# R7FA8M1AH register map
Vendor: Renesas; Series: RA8; File version: 1.2
CPU: CM85 r0p0, little endian, MPU, FPU, VTOR, 4 interrupt priority bits
Registers are 32-bit, read-write, reset 0x0 unless marked. A register's access mark holds for its fields unless they carry their own. Offsets are from the block's base; [hi:lo] are bit positions.

## EDMAC0 — DMA Controller for the Ethernet Controller Channel 0
Base 0x40354000
Same registers: EDMAC0_NS 0x50354000
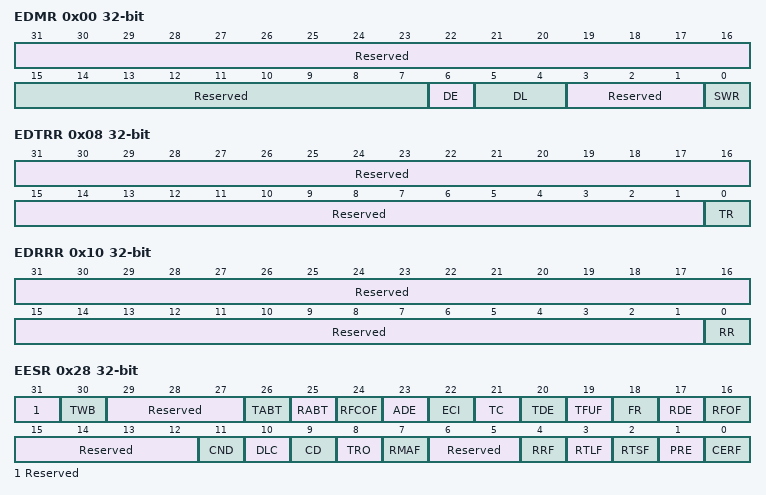
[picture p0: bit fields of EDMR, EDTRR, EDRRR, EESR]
0x00 EDMR — EDMAC Mode Register
  [31:16] Reserved — These bits are read as 0000000000000000. The write value should be 0000000000000000.
  [15:7] Reserved — These bits are read as 000000000. The write value should be 000000000.
  [6] DE — Big Endian Mode/Little Endian ModeNOTE: This setting applies to data for the transmit/receive buffer. It does not apply to transmit/receive descriptors and registers.
    0=Big endian mode; 1=Little endian mode
  [5:4] DL — Transmit/Receive DescriptorLength
    0=16 bytes; 1=32 bytes; 2=64 bytes; 3=16 bytes
  [3:1] Reserved — These bits are read as 000. The write value should be 000.
  [0] SWR wo — Software Reset
    0=no effect; 1=the corresponding channels of the EDMAC and ETHERC are reset. Registers TDLAR, RDLAR, RMFCR, TFUCR, and RFOCR are not reset.
0x08 EDTRR — EDMAC Transmit Request Register
  [31:1] Reserved — These bits are read as 0000000000000000000000000000000. The write value should be 0000000000000000000000000000000.
  [0] TR wo — Transmit Request
    0=no effect; 1=When 1 is written, the EDMAC reads the corresponding descriptor and transmits frames where the TD0.TACT bit is 1. The TR bit becomes 0 after all the valid frames are transmitted.
0x10 EDRRR — EDMAC Receive Request Register
  [31:1] Reserved — These bits are read as 0000000000000000000000000000000. The write value should be 0000000000000000000000000000000.
  [0] RR — Receive Request
    0=Receive function is disabled; 1=Receive descriptor is read, and the receive function is enabled
0x18 TDLAR — Transmit Descriptor List Start Address Register
  [31:0] TDLAR — The start address of the transmit descriptor list is set. Set the start address according to the descriptor length selected by the EDMR.DL[1:0] bits.16-byte boundary: Lower 4 bits = 0000b32-byte boundary: Lower 5 bits = 00000b64-byte boundary: Lower 6 bits = 000000b
0x20 RDLAR — Receive Descriptor List Start Address Register
  [31:0] RDLAR — The start address of the receive descriptor list is set. Set the start address according to the descriptor length selected by the EDMR.DL[1:0] bits.16-byte boundary: Lower 4 bits = 0000b32-byte boundary: Lower 5 bits = 00000b64-byte boundary: Lower 6 bits = 000000b
0x28 EESR — ETHERC/EDMAC Status Register
  [31] Reserved — This bit is read as 0. The write value should be 0.
  [30] TWB write-1-clears read-modifies — Write-Back Complete Flag
    0=Write-back has not been completed, or no transmission has been requested; 1=Write-back to the transmit descriptor has been completed
  [29:27] Reserved — These bits are read as 000. The write value should be 000.
  [26] TABT write-1-clears read-modifies — Transmit Abort Detect Flag
    0=Frame transmission has not been aborted or no transmission has been requested; 1=Frame transmission has been aborted
  [25] RABT write-1-clears read-modifies — Receive Abort Detect Flag
    0=Frame reception has not been aborted or no reception has been requested; 1=Frame reception has been aborted
  [24] RFCOF write-1-clears read-modifies — Receive Frame Counter Overflow Flag
    0=Receive frame counter has not overflowed; 1=Receive frame counter has overflowed
  [23] ADE write-1-clears read-modifies — Address Error Flag
    0=Invalid memory address has not been detected (normal operation); 1=Invalid memory address has been detected
  [22] ECI ro — ETHERC Status Register Source FlagNOTE: When the source in the ETHERCn.ECSR register is cleared, the ECI flag is also cleared.
    0=ETHERC status interrupt source has not been detected; 1=ETHERC status interrupt source has been detected
  [21] TC write-1-clears read-modifies — Frame Transfer Complete Flag
    0=Transfer have not been completed, or no transfer has been requested; 1=All frames indicated by the transmit descriptor have been completely transferred to the transmit FIFO
  [20] TDE write-1-clears read-modifies — Transmit Descriptor Empty Flag
    0=The EDMAC detects that the transmit descriptor valid bit (TDn.TACT) is 1; 1=The EDMAC detects that the transmit descriptor valid bit (TDn.TACT) is 0
  [19] TFUF write-1-clears read-modifies — Transmit FIFO Underflow Flag
    0=Underflow has not occurred; 1=Underflow has occurred
  [18] FR write-1-clears read-modifies — Frame Receive Flag
    0=Frame has not been received; 1=Frame has been received. Update of the receive descriptor is complete.
  [17] RDE write-1-clears read-modifies — Receive Descriptor Empty Flag
    0=The EDMAC detects that the receive descriptor valid bit (RDn.RACT) is 1; 1=The EDMAC detects that the receive descriptor valid bit (RDn.RACT) is 0
  [16] RFOF write-1-clears read-modifies — Receive FIFO Overflow Flag
    0=Overflow has not occurred; 1=Overflow has occurred
  [15:12] Reserved — These bits are read as 0000. The write value should be 0000.
  [11] CND write-1-clears read-modifies — Carrier Not Detect Flag
    0=A carrier has been detected when transmission starts; 1=A carrier has not been detected during preamble transmission
  [10] DLC write-1-clears read-modifies — Loss of Carrier Detect Flag
    0=Loss of carrier has not been detected; 1=Loss of carrier has been detected during frame transmission
  [9] CD write-1-clears read-modifies — Late Collision Detect Flag
    0=Late collision has not been detected; 1=Late collision has been detected during frame transmission
  [8] TRO write-1-clears read-modifies — Transmit Retry Over Flag
    0=Transmit retry-over condition has not been detected; 1=Transmit retry-over condition has been detected
  [7] RMAF write-1-clears read-modifies — Multicast Address Frame Receive Flag
    0=Multicast address frame has not been received; 1=Multicast address frame has been received
  [6:5] Reserved — These bits are read as 00. The write value should be 00.
  [4] RRF write-1-clears read-modifies — Alignment Error Flag
    0=Alignment error has not been detected; 1=Alignment error has been detected
  [3] RTLF write-1-clears read-modifies — Frame-Too-Long Error Flag
    0=Frame-too-long error has not been detected; 1=Frame-too-long error has been detected
  [2] RTSF write-1-clears read-modifies — Frame-Too-Short Error Flag
    0=Frame-too-short error has not been detected; 1=Frame-too-short error has been detected
  [1] PRE write-1-clears read-modifies — PHY-LSI Receive Error Flag
    0=PHY-LSI receive error has not been detected; 1=PHY-LSI receive error has been detected
  [0] CERF write-1-clears read-modifies — CRC Error Flag
    0=CRC error has not been detected; 1=CRC error has been detected
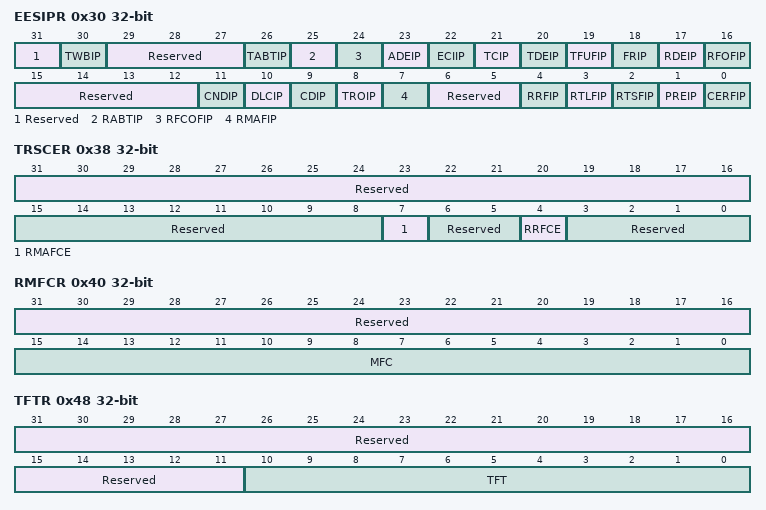
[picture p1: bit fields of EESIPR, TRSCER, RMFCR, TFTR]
0x30 EESIPR — ETHERC/EDMAC Status Interrupt Enable Register
  [31] Reserved — This bit is read as 0. The write value should be 0.
  [30] TWBIP — Write-Back Complete Interrupt Request Enable
    0=Write-back complete interrupt request is disabled; 1=Write-back complete interrupt request is enabled
  [29:27] Reserved — These bits are read as 000. The write value should be 000.
  [26] TABTIP — Transmit Abort Detect Interrupt Request Enable
    0=Transmit abort detect interrupt request is disabled; 1=Transmit abort detect interrupt request is enabled
  [25] RABTIP — Receive Abort Detect Interrupt Request Enable
    0=Receive abort detect interrupt request is disabled; 1=Receive abort detect interrupt request is enabled
  [24] RFCOFIP — Receive Frame Counter Overflow Interrupt Request Enable
    0=Receive frame counter overflow interrupt request is disabled; 1=Receive frame counter overflow interrupt request is enabled
  [23] ADEIP — Address Error Interrupt Request Enable
    0=Address error interrupt request is disabled; 1=Address error interrupt request is enabled
  [22] ECIIP — ETHERC Status Register Source Interrupt Request Enable
    0=ETHERC status interrupt request is disabled; 1=ETHERC status interrupt request is enabled
  [21] TCIP — Frame Transfer Complete Interrupt Request Enable
    0=Frame transmission complete interrupt request is disabled; 1=Frame transmission complete interrupt request is enabled
  [20] TDEIP — Transmit Descriptor Empty Interrupt Request Enable
    0=Transmit descriptor empty interrupt request is disabled; 1=Transmit descriptor empty interrupt request is enabled
  [19] TFUFIP — Transmit FIFO Underflow Interrupt Request Enable
    0=Underflow interrupt request is disabled; 1=Underflow interrupt request is enabled
  [18] FRIP — Frame Receive Interrupt Request Enable
    0=Frame reception interrupt request is disabled; 1=Frame reception interrupt request is enabled
  [17] RDEIP — Receive Descriptor Empty Interrupt Request Enable
    0=Receive descriptor empty interrupt request is disabled; 1=Receive descriptor empty interrupt request is enabled
  [16] RFOFIP — Receive FIFO Overflow Interrupt Request Enable
    0=Overflow interrupt request is disabled; 1=Overflow interrupt request is enabled
  [15:12] Reserved — These bits are read as 0000. The write value should be 0000.
  [11] CNDIP — Carrier Not Detect Interrupt Request Enable
    0=Carrier not detect interrupt request is disabled; 1=Carrier not detect interrupt request is enabled
  [10] DLCIP — Loss of Carrier Detect Interrupt Request Enable
    0=Loss of carrier detect interrupt request is disabled; 1=Loss of carrier detect interrupt request is enabled
  [9] CDIP — Late Collision Detect Interrupt Request Enable
    0=Late collision detect interrupt request is disabled; 1=Late collision detect interrupt request is enabled
  [8] TROIP — Transmit Retry Over Interrupt Request Enable
    0=Transmit retry over interrupt request is disabled; 1=Transmit retry over interrupt request is enabled
  [7] RMAFIP — Multicast Address Frame Receive Interrupt Request Enable
    0=Multicast address frame receive interrupt request is disabled; 1=Multicast address frame receive interrupt request is enabled
  [6:5] Reserved — These bits are read as 00. The write value should be 00.
  [4] RRFIP — Alignment Error Interrupt Request Enable
    0=Alignment error interrupt request is disabled; 1=Alignment error interrupt request is enabled
  [3] RTLFIP — Frame-Too-Long Error Interrupt Request Enable
    0=Frame-too-long error interrupt request is disabled; 1=Frame-too-long error interrupt request is enabled
  [2] RTSFIP — Frame-Too-Short Error Interrupt Request Enable
    0=Frame-too-short error interrupt request is disabled; 1=Frame-too-short error interrupt request is enabled
  [1] PREIP — PHY-LSI Receive Error Interrupt Request Enable
    0=PHY-LSI receive error interrupt request is disabled; 1=PHY-LSI receive error interrupt request is enabled
  [0] CERFIP — CRC Error Interrupt Request Enable
    0=CRC error interrupt request is disabled; 1=CRC error interrupt request is enabled
0x38 TRSCER — ETHERC/EDMAC Transmit/Receive Status Copy Enable Register
  [31:16] Reserved — These bits are read as 0000000000000000. The write value should be 0000000000000000.
  [15:8] Reserved — These bits are read as 00000000. The write value should be 00000000.
  [7] RMAFCE — RMAF Flag Copy Enable
    0=The EDMACn.EESR.RMAF flag status is reflected in the RDn.RFE bit of the receive descriptor; 1=The EDMACn.EESR.RMAF flag status is not reflected in the RDn.RFE bit of the receive descriptor
  [6:5] Reserved — These bits are read as 00. The write value should be 00.
  [4] RRFCE — RRF Flag Copy Enable
    0=The EDMACn.EESR.RRF flag status is reflected in the RDn.RFE bit of the receive descriptor; 1=The EDMACn.EESR.RRF flag status is not reflected in the RDn.RFE bit of the receive descriptor
  [3:0] Reserved — These bits are read as 0000. The write value should be 0000.
0x40 RMFCR — Missed-Frame Counter Register
  [31:16] Reserved — These bits are read as 0000000000000000. The write value should be 0000000000000000.
  [15:0] MFC write-clears — Missed-Frame CounterThese bits indicate the number of frames that are discarded and not transferred to the receive buffer during reception.
0x48 TFTR — Transmit FIFO Threshold Register
  [31:11] Reserved — These bits are read as 000000000000000000000. The write value should be 000000000000000000000.
  [10:0] TFT range 0x000..0x200 — Transmit FIFO Threshold00Dh to 200h: The threshold is the set value multiplied by 4. Example: 00Dh: 52 bytes 040h: 256 bytes 100h: 1024 bytes 200h: 2048 bytes
    0=Store and forward mode; other=others (The threshold is the set value multiplied by 4. (001h to 00Ch and 201h to 7FFh: Setting prohibited))
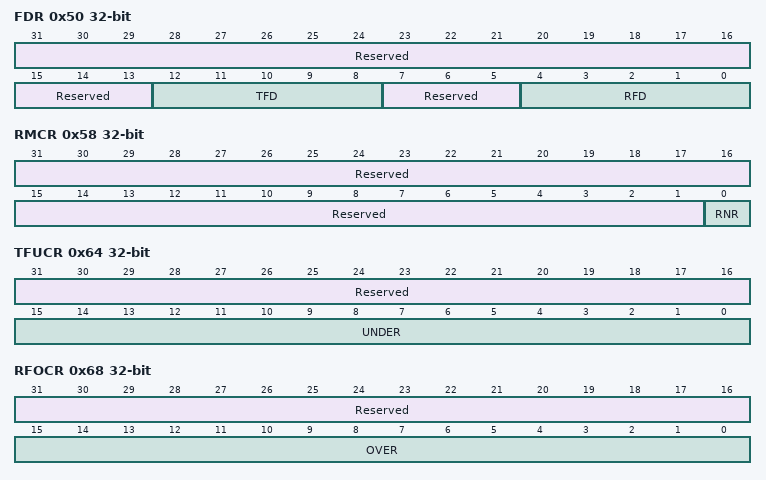
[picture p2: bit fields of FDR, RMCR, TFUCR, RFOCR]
0x50 FDR — Transmit FIFO Threshold Register
  [31:13] Reserved — These bits are read as 0000000000000000000. The write value should be 0000000000000000000.
  [12:8] TFD — Receive FIFO Depth
    15=4096 bytes; other=others (Settings other than above are prohibited.)
  [7:5] Reserved — These bits are read as 000. The write value should be 000.
  [4:0] RFD — Transmit FIFO Depth
    7=2048 bytes; other=others (Settings other than above are prohibited.)
0x58 RMCR — Receive Method Control Register
  [31:1] Reserved — These bits are read as 0000000000000000000000000000000. The write value should be 0000000000000000000000000000000.
  [0] RNR — Receive Request Reset
    0=EDRRR.RR bit (receive request bit) is set to 0 when one frame has been received; 1=EDRRR.RR bit (receive request bit) is not set to 0 when one frame has been received
0x64 TFUCR — Transmit FIFO Underflow Counter
  [31:16] Reserved — These bits are read as 0000000000000000. The write value should be 0000000000000000.
  [15:0] UNDER — Transmit FIFO Underflow CountThese bits indicate how many times the transmit FIFO has underflowed. The counter stops when the counter value reaches FFFFh.
0x68 RFOCR — Receive FIFO Overflow Counter
  [31:16] Reserved — These bits are read as 0000000000000000. The write value should be 0000000000000000.
  [15:0] OVER — Receive FIFO Overflow CountThese bits indicate how many times the receive FIFO has overflowed. The counter stops when the counter value reaches FFFFh.
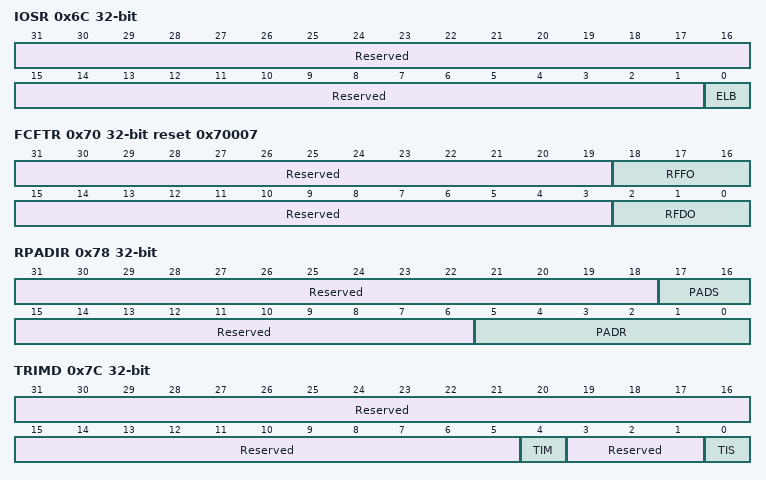
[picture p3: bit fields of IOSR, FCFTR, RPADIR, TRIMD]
0x6C IOSR — Independent Output Signal Setting Register
  [31:1] Reserved — These bits are read as 0000000000000000000000000000000. The write value should be 0000000000000000000000000000000.
  [0] ELB — External Loopback Mode
    0=The ETn_EXOUT pin outputs low; 1=The ETn_EXOUT pin outputs high
0x70 FCFTR reset 0x70007 — Flow Control Start FIFO Threshold Setting Register
  [31:19] Reserved — These bits are read as 0000000000000. The write value should be 0000000000000.
  [18:16] RFFO — Receive FIFO Frame PAUSE Output Threshold(When ((RFFO+1)x2) receive frames have been stored in the receive FIFO.)
    0=When 2 receive frames have been stored in the receive FIFO; 1=When 4 receive frames have been stored in the receive FIFO; 2=When 6 receive frames have been stored in the receive FIFO; 3=When 8 receive frames have been stored in the receive FIFO; 4=When 10 receive frames have been stored in the receive FIFO; 5=When 12 receive frames have been stored in the receive FIFO; 6=When 14 receive frames have been stored in the receive FIFO; 7=When 16 receive frames have been stored in the receive FIFO
  [15:3] Reserved — These bits are read as 0000000000000. The write value should be 0000000000000.
  [2:0] RFDO — Receive FIFO Data PAUSE Output Threshold(When (RFDO+1)x256-32 bytes of data is stored in the receive FIFO.)
    0=When 224 ( 256 - 32) bytes of data is stored in the receive FIFO; 1=When 480 ( 512 - 32) bytes of data is stored in the receive FIFO; 2=When 736 ( 768 - 32) bytes of data is stored in the receive FIFO; 3=When 992 (1024 - 32) bytes of data is stored in the receive FIFO; 4=When 1248 (1280 - 32) bytes of data is stored in the receive FIFO; 5=When 1504 (1536 - 32) bytes of data is stored in the receive FIFO; 6=When 1760 (1792 - 32) bytes of data is stored in the receive FIFO; 7=When 2016 (2048 - 32) bytes of data is stored in the receive FIFO
0x78 RPADIR — Receive Data Padding Insert Register
  [31:18] Reserved — These bits are read as 00000000000000. The write value should be 00000000000000.
  [17:16] PADS — Padding Size
    0=No padding is inserted; 1=1 byte is inserted; 2=2 bytes are inserted; 3=3 bytes are inserted
  [15:6] Reserved — These bits are read as 0000000000. The write value should be 0000000000.
  [5:0] PADR — Padding Slot
    0=00h (Padding is inserted at the head of received data.); other=others (Padding is inserted between the (PADR)th byte and (PADR+1)th byte of received data.)
0x7C TRIMD — Transmit Interrupt Setting Register
  [31:5] Reserved — These bits are read as 000000000000000000000000000. The write value should be 000000000000000000000000000.
  [4] TIM — Transmit Interrupt Mode
    0=Transmission complete interrupt mode: An interrupt occurs when a frame has been transmitted; 1=Write-back complete interrupt mode: An interrupt occurs when write-back to the transmit descriptor has been completed
  [3:1] Reserved — These bits are read as 000. The write value should be 000.
  [0] TIS — Transmit Interrupt EnableSet the EESR.TWB flag to 1 in the mode selected by the TIM bit to notify an interrupt.
    0=Transmit Interrupt is disabled; 1=Transmit Interrupt is enabled
0xC8 RBWAR ro — Receive Buffer Write Address Register
  [31:0] RBWAR — Receive Buffer Write Address RegisterThe RBWAR register indicates the last address that the EDMAC has written data to when writing to the receive buffer.Refer to the address indicated by the RBWAR register to recognize which address in the receive buffer the EDMAC is writing data to. Note that the address that the EDMAC is outputting to the receive buffer may not match the read value of the RBWAR register during data reception.
0xCC RDFAR ro — Receive Descriptor Fetch Address Register
  [31:0] RDFAR — Receive Descriptor Fetch Address RegisterThe RDFAR register indicates the start address of the last fetched receive descriptor when the EDMAC fetches descriptor information from the receive descriptor.Refer to the address indicated by the RDFAR register to recognize which receive descriptor information the EDMAC is using for the current processing. Note that the address of the receive descriptor that the EDMAC fetches may not match the read value of the RDFAR register during data reception.
0xD4 TBRAR ro — Transmit Buffer Read Address Register
  [31:0] TBRAR — Transmit Buffer Read Address RegisterThe TBRAR register indicates the last address that the EDMAC has read data from when reading data from the transmit buffer.Refer to the address indicated by the TBRAR register to recognize which address in the transmit buffer the EDMAC is reading from. Note that the address that the EDMAC is outputting to the transmit buffer may not match the read value of the TBRAR register.
0xD8 TDFAR ro — Transmit Descriptor Fetch Address Register
  [31:0] TDFAR — Transmit Descriptor Fetch Address RegisterThe TDFAR register indicates the start address of the last fetched transmit descriptor when the EDMAC fetches descriptor information from the transmit descriptor.Refer to the address indicated by the TDFAR register to recognize which transmit descriptor information the EDMAC is using for the current processing. Note that the address of the transmit descriptor that the EDMAC fetches may not match the read value of the TDFAR register.
